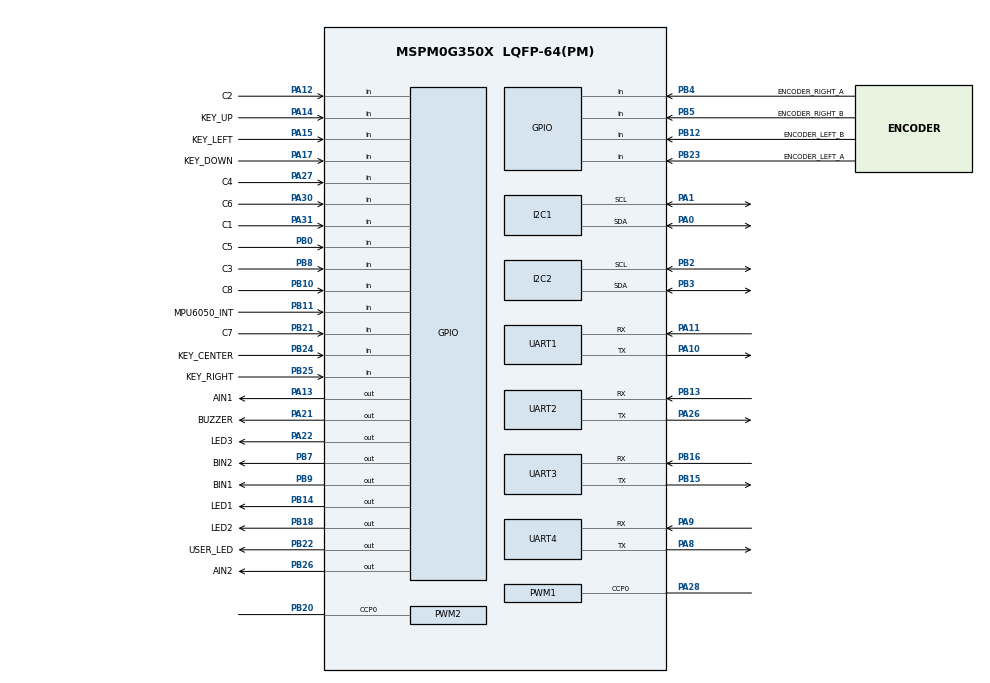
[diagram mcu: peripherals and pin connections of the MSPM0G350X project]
/**
 *
 * @cliArgs --device "MSPM0G350X" --part "Default" --package "LQFP-64(PM)" --product "mspm0_sdk@2.11.00.07"
 * @versions {"tool":"1.28.0+4696"}
 */

/**
 * Import the modules used in this configuration.
 */
const GPIO   = scripting.addModule("/ti/driverlib/GPIO", {}, false);
const GPIO1  = GPIO.addInstance();
const GPIO2  = GPIO.addInstance();
const GPIO3  = GPIO.addInstance();
const GPIO4  = GPIO.addInstance();
const GPIO5  = GPIO.addInstance();
const GPIO6  = GPIO.addInstance();
const GPIO7  = GPIO.addInstance();
const I2C    = scripting.addModule("/ti/driverlib/I2C", {}, false);
const I2C1   = I2C.addInstance();
const I2C2   = I2C.addInstance();
const PWM    = scripting.addModule("/ti/driverlib/PWM", {}, false);
const PWM1   = PWM.addInstance();
const PWM2   = PWM.addInstance();
const SYSCTL = scripting.addModule("/ti/driverlib/SYSCTL");
const UART   = scripting.addModule("/ti/driverlib/UART", {}, false);
const UART1  = UART.addInstance();
const UART2  = UART.addInstance();
const UART3  = UART.addInstance();
const UART4  = UART.addInstance();

/**
 * Write custom configuration values to the imported modules.
 */
GPIO1.$name                         = "GPIO_MOTOR_DIR";
GPIO1.associatedPins.create(4);
GPIO1.associatedPins[0].$name       = "AIN1";
GPIO1.associatedPins[0].pin.$assign = "PA13";
GPIO1.associatedPins[1].$name       = "AIN2";
GPIO1.associatedPins[1].pin.$assign = "PB26";
GPIO1.associatedPins[2].$name       = "BIN1";
GPIO1.associatedPins[2].pin.$assign = "PB9";
GPIO1.associatedPins[3].$name       = "BIN2";
GPIO1.associatedPins[3].pin.$assign = "PB7";

const Board = scripting.addModule("/ti/driverlib/Board", {}, false);

GPIO2.$name                         = "GPIO_LINE_SENSOR";
GPIO2.associatedPins.create(8);
GPIO2.associatedPins[0].direction   = "INPUT";
GPIO2.associatedPins[0].$name       = "C1";
GPIO2.associatedPins[0].pin.$assign = "PA31";
GPIO2.associatedPins[1].direction   = "INPUT";
GPIO2.associatedPins[1].$name       = "C2";
GPIO2.associatedPins[1].pin.$assign = "PA12";
GPIO2.associatedPins[2].direction   = "INPUT";
GPIO2.associatedPins[2].$name       = "C3";
GPIO2.associatedPins[2].pin.$assign = "PB8";
GPIO2.associatedPins[3].direction   = "INPUT";
GPIO2.associatedPins[3].$name       = "C4";
GPIO2.associatedPins[3].pin.$assign = "PA27";
GPIO2.associatedPins[4].$name       = "C5";
GPIO2.associatedPins[4].direction   = "INPUT";
GPIO2.associatedPins[4].pin.$assign = "PB0";
GPIO2.associatedPins[5].$name       = "C6";
GPIO2.associatedPins[5].direction   = "INPUT";
GPIO2.associatedPins[5].pin.$assign = "PA30";
GPIO2.associatedPins[6].$name       = "C7";
GPIO2.associatedPins[6].direction   = "INPUT";
GPIO2.associatedPins[6].pin.$assign = "PB21";
GPIO2.associatedPins[7].$name       = "C8";
GPIO2.associatedPins[7].direction   = "INPUT";
GPIO2.associatedPins[7].pin.$assign = "PB10";

GPIO3.$name                         = "GPIO_ENCODER";
GPIO3.associatedPins.create(4);
GPIO3.associatedPins[0].$name       = "ENCODER_LEFT_A";
GPIO3.associatedPins[0].direction   = "INPUT";
GPIO3.associatedPins[0].interruptEn = true;
GPIO3.associatedPins[0].polarity    = "RISE_FALL";
GPIO3.associatedPins[0].pin.$assign = "PB23";
GPIO3.associatedPins[1].$name       = "ENCODER_LEFT_B";
GPIO3.associatedPins[1].direction   = "INPUT";
GPIO3.associatedPins[1].interruptEn = true;
GPIO3.associatedPins[1].polarity    = "RISE_FALL";
GPIO3.associatedPins[1].pin.$assign = "PB12";
GPIO3.associatedPins[2].$name       = "ENCODER_RIGHT_A";
GPIO3.associatedPins[2].direction   = "INPUT";
GPIO3.associatedPins[2].interruptEn = true;
GPIO3.associatedPins[2].polarity    = "RISE_FALL";
GPIO3.associatedPins[2].pin.$assign = "PB4";
GPIO3.associatedPins[3].$name       = "ENCODER_RIGHT_B";
GPIO3.associatedPins[3].direction   = "INPUT";
GPIO3.associatedPins[3].interruptEn = true;
GPIO3.associatedPins[3].polarity    = "RISE_FALL";
GPIO3.associatedPins[3].pin.$assign = "PB5";

GPIO4.$name                         = "GPIO_MPU6050_DATA_READY";
GPIO4.associatedPins[0].$name       = "MPU6050_INT";
GPIO4.associatedPins[0].direction   = "INPUT";
GPIO4.associatedPins[0].interruptEn = true;
GPIO4.associatedPins[0].polarity    = "RISE";
GPIO4.associatedPins[0].pin.$assign = "PB11";

GPIO5.$name                          = "GPIO_LED";
GPIO5.associatedPins.create(4);
GPIO5.associatedPins[0].$name        = "LED1";
GPIO5.associatedPins[0].initialValue = "SET";
GPIO5.associatedPins[0].pin.$assign  = "PB14";
GPIO5.associatedPins[1].$name        = "LED2";
GPIO5.associatedPins[1].initialValue = "SET";
GPIO5.associatedPins[1].pin.$assign  = "PB18";
GPIO5.associatedPins[2].$name        = "LED3";
GPIO5.associatedPins[2].initialValue = "SET";
GPIO5.associatedPins[2].pin.$assign  = "PA22";
GPIO5.associatedPins[3].$name        = "USER_LED";
GPIO5.associatedPins[3].pin.$assign  = "PB22";

GPIO6.$name                              = "GPIO_KEY";
GPIO6.associatedPins.create(5);
GPIO6.associatedPins[0].$name            = "KEY_UP";
GPIO6.associatedPins[0].direction        = "INPUT";
GPIO6.associatedPins[0].internalResistor = "PULL_UP";
GPIO6.associatedPins[0].pin.$assign      = "PA14";
GPIO6.associatedPins[1].$name            = "KEY_LEFT";
GPIO6.associatedPins[1].direction        = "INPUT";
GPIO6.associatedPins[1].internalResistor = "PULL_UP";
GPIO6.associatedPins[1].pin.$assign      = "PA15";
GPIO6.associatedPins[2].$name            = "KEY_DOWN";
GPIO6.associatedPins[2].direction        = "INPUT";
GPIO6.associatedPins[2].internalResistor = "PULL_UP";
GPIO6.associatedPins[2].pin.$assign      = "PA17";
GPIO6.associatedPins[3].$name            = "KEY_RIGHT";
GPIO6.associatedPins[3].direction        = "INPUT";
GPIO6.associatedPins[3].internalResistor = "PULL_UP";
GPIO6.associatedPins[3].pin.$assign      = "PB25";
GPIO6.associatedPins[4].$name            = "KEY_CENTER";
GPIO6.associatedPins[4].direction        = "INPUT";
GPIO6.associatedPins[4].internalResistor = "PULL_UP";
GPIO6.associatedPins[4].pin.$assign      = "PB24";

GPIO7.$name                          = "GPIO_BUZZER";
GPIO7.associatedPins[0].$name        = "BUZZER";
GPIO7.associatedPins[0].initialValue = "SET";
GPIO7.associatedPins[0].ioStructure  = "SD";
GPIO7.associatedPins[0].pin.$assign  = "PA21";

I2C1.$name                             = "I2C_MPU6050";
I2C1.basicEnableController             = true;
I2C1.basicControllerStandardBusSpeed   = "Fast";
I2C1.peripheral.sdaPin.$assign         = "PA0";
I2C1.peripheral.sclPin.$assign         = "PA1";
I2C1.sdaPinConfig.$name                = "ti_driverlib_gpio_GPIOPinGeneric0";
I2C1.sdaPinConfig.hideOutputInversion  = scripting.forceWrite(false);
I2C1.sdaPinConfig.onlyInternalResistor = scripting.forceWrite(false);
I2C1.sdaPinConfig.passedPeripheralType = scripting.forceWrite("Digital");
I2C1.sclPinConfig.$name                = "ti_driverlib_gpio_GPIOPinGeneric1";
I2C1.sclPinConfig.hideOutputInversion  = scripting.forceWrite(false);
I2C1.sclPinConfig.onlyInternalResistor = scripting.forceWrite(false);
I2C1.sclPinConfig.passedPeripheralType = scripting.forceWrite("Digital");

I2C2.$name                             = "I2C_OLED";
I2C2.basicEnableController             = true;
I2C2.basicControllerStandardBusSpeed   = "Fast";
I2C2.peripheral.sdaPin.$assign         = "PB3";
I2C2.peripheral.sclPin.$assign         = "PB2";
I2C2.sdaPinConfig.hideOutputInversion  = scripting.forceWrite(false);
I2C2.sdaPinConfig.onlyInternalResistor = scripting.forceWrite(false);
I2C2.sdaPinConfig.passedPeripheralType = scripting.forceWrite("Digital");
I2C2.sdaPinConfig.$name                = "ti_driverlib_gpio_GPIOPinGeneric12";
I2C2.sclPinConfig.hideOutputInversion  = scripting.forceWrite(false);
I2C2.sclPinConfig.onlyInternalResistor = scripting.forceWrite(false);
I2C2.sclPinConfig.passedPeripheralType = scripting.forceWrite("Digital");
I2C2.sclPinConfig.$name                = "ti_driverlib_gpio_GPIOPinGeneric13";

PWM1.$name                              = "PWM_MOTOR";
PWM1.timerCount                         = 8000;
PWM1.timerStartTimer                    = true;
PWM1.ccIndex                            = [0];
PWM1.PWM_CHANNEL_0.$name                = "ti_driverlib_pwm_PWMTimerCC0";
PWM1.ccp0PinConfig.$name                = "ti_driverlib_gpio_GPIOPinGeneric4";
PWM1.ccp0PinConfig.direction            = scripting.forceWrite("OUTPUT");
PWM1.ccp0PinConfig.hideOutputInversion  = scripting.forceWrite(false);
PWM1.ccp0PinConfig.onlyInternalResistor = scripting.forceWrite(false);
PWM1.ccp0PinConfig.passedPeripheralType = scripting.forceWrite("Digital");
PWM1.peripheral.$assign                 = "TIMA1";
PWM1.peripheral.ccp0Pin.$assign         = "PA28";

PWM2.$name                              = "PWM_MOTOR_B";
PWM2.ccIndex                            = [0];
PWM2.timerCount                         = 8000;
PWM2.timerStartTimer                    = true;
PWM2.PWM_CHANNEL_0.$name                = "ti_driverlib_pwm_PWMTimerCC2";
PWM2.ccp0PinConfig.$name                = "ti_driverlib_gpio_GPIOPinGeneric6";
PWM2.ccp0PinConfig.direction            = scripting.forceWrite("OUTPUT");
PWM2.ccp0PinConfig.hideOutputInversion  = scripting.forceWrite(false);
PWM2.ccp0PinConfig.onlyInternalResistor = scripting.forceWrite(false);
PWM2.ccp0PinConfig.passedPeripheralType = scripting.forceWrite("Digital");
PWM2.peripheral.ccp0Pin.$assign         = "PB20";

SYSCTL.SYSPLL_CLK0En     = true;
SYSCTL.MCLKSource        = "HSCLK";
SYSCTL.validateClkStatus = true;
SYSCTL.HFCLKSource       = "HFXT";
SYSCTL.HFCLK_Freq        = 40000000;
SYSCTL.LFCLKSource       = "LFXT";
SYSCTL.SYSPLLSource      = "HFCLK";
SYSCTL.SYSPLL_Qdiv       = 8;
SYSCTL.useHFCLK_Manual   = true;

UART1.$name                            = "UART_CONSOLE";
UART1.targetBaudRate                   = 115200;
UART1.enableFIFO                       = true;
UART1.enabledInterrupts                = ["RX","TX"];
UART1.rxFifoThreshold                  = "DL_UART_RX_FIFO_LEVEL_ONE_ENTRY";
UART1.peripheral.rxPin.$assign         = "PA11";
UART1.peripheral.txPin.$assign         = "PA10";
UART1.txPinConfig.direction            = scripting.forceWrite("OUTPUT");
UART1.txPinConfig.hideOutputInversion  = scripting.forceWrite(false);
UART1.txPinConfig.onlyInternalResistor = scripting.forceWrite(false);
UART1.txPinConfig.passedPeripheralType = scripting.forceWrite("Digital");
UART1.txPinConfig.$name                = "ti_driverlib_gpio_GPIOPinGeneric2";
UART1.rxPinConfig.hideOutputInversion  = scripting.forceWrite(false);
UART1.rxPinConfig.onlyInternalResistor = scripting.forceWrite(false);
UART1.rxPinConfig.passedPeripheralType = scripting.forceWrite("Digital");
UART1.rxPinConfig.$name                = "ti_driverlib_gpio_GPIOPinGeneric3";

UART2.$name                            = "UART3_MODULE";
UART2.targetBaudRate                   = 115200;
UART2.enableFIFO                       = true;
UART2.peripheral.rxPin.$assign         = "PB13";
UART2.peripheral.txPin.$assign         = "PA26";
UART2.txPinConfig.direction            = scripting.forceWrite("OUTPUT");
UART2.txPinConfig.hideOutputInversion  = scripting.forceWrite(false);
UART2.txPinConfig.onlyInternalResistor = scripting.forceWrite(false);
UART2.txPinConfig.passedPeripheralType = scripting.forceWrite("Digital");
UART2.txPinConfig.$name                = "ti_driverlib_gpio_GPIOPinGeneric5";
UART2.rxPinConfig.hideOutputInversion  = scripting.forceWrite(false);
UART2.rxPinConfig.onlyInternalResistor = scripting.forceWrite(false);
UART2.rxPinConfig.passedPeripheralType = scripting.forceWrite("Digital");
UART2.rxPinConfig.$name                = "ti_driverlib_gpio_GPIOPinGeneric7";

UART3.$name                            = "UART2_MODULE";
UART3.targetBaudRate                   = 115200;
UART3.enableFIFO                       = true;
UART3.peripheral.rxPin.$assign         = "PB16";
UART3.peripheral.txPin.$assign         = "PB15";
UART3.txPinConfig.direction            = scripting.forceWrite("OUTPUT");
UART3.txPinConfig.hideOutputInversion  = scripting.forceWrite(false);
UART3.txPinConfig.onlyInternalResistor = scripting.forceWrite(false);
UART3.txPinConfig.passedPeripheralType = scripting.forceWrite("Digital");
UART3.txPinConfig.$name                = "ti_driverlib_gpio_GPIOPinGeneric8";
UART3.rxPinConfig.hideOutputInversion  = scripting.forceWrite(false);
UART3.rxPinConfig.onlyInternalResistor = scripting.forceWrite(false);
UART3.rxPinConfig.passedPeripheralType = scripting.forceWrite("Digital");
UART3.rxPinConfig.$name                = "ti_driverlib_gpio_GPIOPinGeneric9";

UART4.$name                            = "UART1_MODULE";
UART4.targetBaudRate                   = 115200;
UART4.enableFIFO                       = true;
UART4.peripheral.rxPin.$assign         = "PA9";
UART4.peripheral.txPin.$assign         = "PA8";
UART4.txPinConfig.direction            = scripting.forceWrite("OUTPUT");
UART4.txPinConfig.hideOutputInversion  = scripting.forceWrite(false);
UART4.txPinConfig.onlyInternalResistor = scripting.forceWrite(false);
UART4.txPinConfig.passedPeripheralType = scripting.forceWrite("Digital");
UART4.txPinConfig.$name                = "ti_driverlib_gpio_GPIOPinGeneric10";
UART4.rxPinConfig.hideOutputInversion  = scripting.forceWrite(false);
UART4.rxPinConfig.onlyInternalResistor = scripting.forceWrite(false);
UART4.rxPinConfig.passedPeripheralType = scripting.forceWrite("Digital");
UART4.rxPinConfig.$name                = "ti_driverlib_gpio_GPIOPinGeneric11";

/**
 * Pinmux solution for unlocked pins/peripherals. This ensures that minor changes to the automatic solver in a future
 * version of the tool will not impact the pinmux you originally saw.  These lines can be completely deleted in order to
 * re-solve from scratch.
 */
Board.peripheral.$suggestSolution            = "DEBUGSS";
Board.peripheral.swclkPin.$suggestSolution   = "PA20";
Board.peripheral.swdioPin.$suggestSolution   = "PA19";
I2C1.peripheral.$suggestSolution             = "I2C0";
I2C2.peripheral.$suggestSolution             = "I2C1";
PWM2.peripheral.$suggestSolution             = "TIMG12";
SYSCTL.peripheral.$suggestSolution           = "SYSCTL";
SYSCTL.peripheral.lfxInPin.$suggestSolution  = "PA3";
SYSCTL.peripheral.lfxOutPin.$suggestSolution = "PA4";
SYSCTL.peripheral.hfxInPin.$suggestSolution  = "PA5";
SYSCTL.peripheral.hfxOutPin.$suggestSolution = "PA6";
UART1.peripheral.$suggestSolution            = "UART0";
UART2.peripheral.$suggestSolution            = "UART3";
UART3.peripheral.$suggestSolution            = "UART2";
UART4.peripheral.$suggestSolution            = "UART1";
